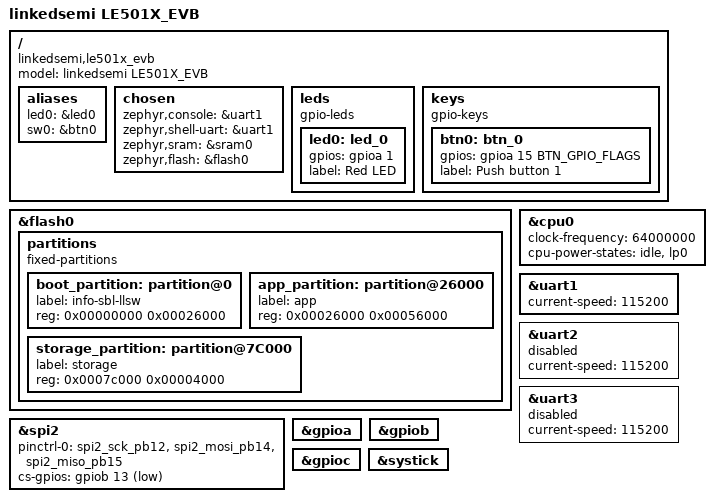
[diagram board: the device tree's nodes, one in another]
/*
 * Copyright (c) 2023 Linkedsemi
 * SPDX-License-Identifier: Apache-2.0
 */

/dts-v1/;
#include <linkedsemi/le501x.dtsi>
#include "le501x_evb-pinctrl.dtsi"

#define BTN_GPIO_FLAGS (GPIO_ACTIVE_LOW | GPIO_PULL_UP)

/ {
	model = "linkedsemi LE501X_EVB";
	compatible = "linkedsemi,le501x_evb";
    
    aliases {
		led0 = &led0;
        sw0 = &btn0;
	};

	chosen {
		zephyr,console = &uart1;
		zephyr,shell-uart = &uart1;
		zephyr,sram = &sram0;
		zephyr,flash = &flash0;
	};

    leds {
		compatible = "gpio-leds";
        led0: led_0 {
            gpios = <&gpioa 1 GPIO_ACTIVE_HIGH>;
            label = "Red LED";
        };
    };

    keys {
		compatible = "gpio-keys";
		btn0: btn_0 {
			gpios = <&gpioa 15 BTN_GPIO_FLAGS>;
			label = "Push button 1";
		};
	};
};

&flash0 {

    /*
	* Flash base address is 0x18000000,
    * the following parts are all offset addresses.
	*/

	partitions {
		compatible = "fixed-partitions";
		#address-cells = <1>;
		#size-cells = <1>;

		boot_partition: partition@0 {
			label = "info-sbl-llsw";
			reg = <0x00000000 0x00026000>;
		};
	
        app_partition: partition@26000 {
			label = "app";
			reg = <0x00026000 0x00056000>;
		};

		/*
		 * The flash starting at 0x1807C000 and ending at
		 * 0x1807FFFF is reserved for use by the application.
		 */

		/*
		 * Storage partition will be used by FCB/LittleFS/NVS
		 * if enabled.
		 */
		storage_partition: partition@7C000 {
			label = "storage";
			reg = <0x0007c000 0x00004000>;
		};
	};
};

&cpu0 {
	clock-frequency = <64000000>;
    cpu-power-states = <&idle &lp0>;
};

&uart1 {
	status = "okay";

	current-speed = <115200>;
};

&uart2 {
	status = "disabled";

	current-speed = <115200>;
};

&uart3{
	status = "disabled";

	current-speed = <115200>;
};

&spi2 {
    status = "okay";
    pinctrl-0 = <&spi2_sck_pb12
                 &spi2_mosi_pb14 &spi2_miso_pb15>;
	pinctrl-names = "default";

	cs-gpios = <&gpiob 13 GPIO_ACTIVE_LOW>;
};

&gpioa {
	status = "okay";
};

&gpiob {
	status = "okay";
};

&gpioc {
	status = "okay";
};

&systick {
	status = "okay";
};

